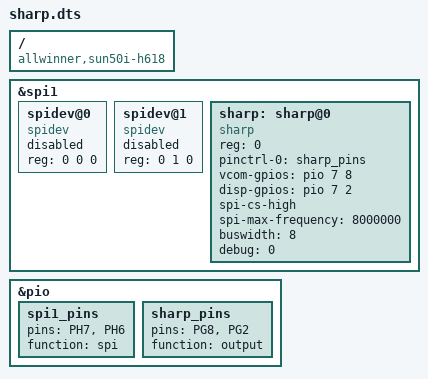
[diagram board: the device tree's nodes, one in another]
/dts-v1/;
/plugin/;

/ {
	compatible = "allwinner,sun50i-h618", "allwinner,sunxi";

	fragment@0 {
		target = <&spi1>;  /* Updated to SPI1 */
		__overlay__ {
			#address-cells = <2>;  /* Two cells for addressing */
			#size-cells = <1>;     /* One cell for size */
			status = "okay";

			spidev@0 {
				compatible = "spidev";
				reg = <0 0 0>; /* Using two address cells and one size cell */
				status = "disabled";
			};

			spidev@1 {
				compatible = "spidev";
				reg = <0 1 0>; /* Using two address cells and one size cell */
				status = "disabled";
			};
		};
	};

	fragment@1 {
		target = <&pio>;
		__overlay__ {
			spi1_pins: spi1_pins {
				pins = "PH7", "PH6"; /* Adjust based on H618 SPI1 pin definitions */
				function = "spi"; /* SPI configuration */
			};
		};
	};

	fragment@2 {
		target = <&pio>;
		__overlay__ {
			sharp_pins: sharp_pins {
				pins = "PG8", "PG2"; /* Updated to actual GPIOs for H618 */
				function = "output"; /* Configuring as output pins */
			};
		};
	};

	fragment@3 {
		target = <&spi1>;  /* Updated to SPI1 */
		__overlay__ {
			#address-cells = <1>;
			#size-cells = <0>;

			sharp: sharp@0 {
				compatible = "sharp";
				reg = <0>; /* SPI device on CS 0 */
				pinctrl-names = "default";
				pinctrl-0 = <&sharp_pins>;

				vcom-gpios = <&pio 7 8 0>; /* PG8 mapped to vcom */
				disp-gpios = <&pio 7 2 0>; /* PG2 mapped to display control */

				spi-cs-high;
				spi-max-frequency = <8000000>; /* Maximum SPI frequency */
				buswidth = <8>; /* 8-bit communication */
				debug = <0>;
			};
		};
	};
};
